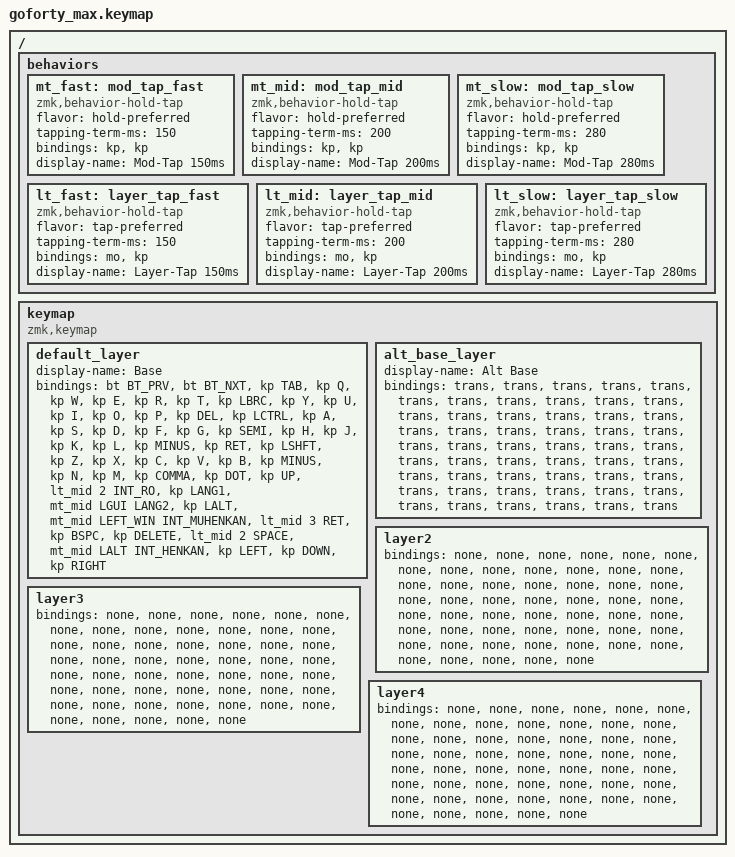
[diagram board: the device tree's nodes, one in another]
#include <behaviors.dtsi>
#include <behaviors/runtime_macro.dtsi>
#include <dt-bindings/zmk/bt.h>
#include <behaviors/runtime_tap_dance.dtsi>
#include <dt-bindings/zmk/keys.h>
#include <dt-bindings/zmk/pointing.h>

/ {
    behaviors {
        /* --- タップ/ホールドの判定時間プリセット ---
           押している時間がここで指定した ms を超えたら「ホールド」、
           それより短ければ「タップ」と判定される。
           数値ちがいのインスタンスを並べて定義しておくと、Keeb-On! Studio の
           キー割り当て候補にそのまま並び、キーごとに好みの速さを選べる。
           値そのものはコンパイル時固定だが、ファームウェアはタグを打てば
           GitHub Releases から配布されるので、合わなければ数値を変えて再配布する。

           flavor は ZMK 標準に合わせてある:
             mod-tap 系   = hold-preferred (ZMK の &mt と同じ)
             layer-tap 系 = tap-preferred  (ZMK の &lt と同じ)
           なので mt_mid / lt_mid は標準の &mt / &lt と完全に同じ挙動になる。 */

        mt_fast: mod_tap_fast {
            compatible = "zmk,behavior-hold-tap";
            #binding-cells = <2>;
            flavor = "hold-preferred";
            tapping-term-ms = <150>;
            bindings = <&kp>, <&kp>;
            display-name = "Mod-Tap 150ms";
        };

        mt_mid: mod_tap_mid {
            compatible = "zmk,behavior-hold-tap";
            #binding-cells = <2>;
            flavor = "hold-preferred";
            tapping-term-ms = <200>;
            bindings = <&kp>, <&kp>;
            display-name = "Mod-Tap 200ms";
        };

        mt_slow: mod_tap_slow {
            compatible = "zmk,behavior-hold-tap";
            #binding-cells = <2>;
            flavor = "hold-preferred";
            tapping-term-ms = <280>;
            bindings = <&kp>, <&kp>;
            display-name = "Mod-Tap 280ms";
        };

        lt_fast: layer_tap_fast {
            compatible = "zmk,behavior-hold-tap";
            #binding-cells = <2>;
            flavor = "tap-preferred";
            tapping-term-ms = <150>;
            bindings = <&mo>, <&kp>;
            display-name = "Layer-Tap 150ms";
        };

        lt_mid: layer_tap_mid {
            compatible = "zmk,behavior-hold-tap";
            #binding-cells = <2>;
            flavor = "tap-preferred";
            tapping-term-ms = <200>;
            bindings = <&mo>, <&kp>;
            display-name = "Layer-Tap 200ms";
        };

        lt_slow: layer_tap_slow {
            compatible = "zmk,behavior-hold-tap";
            #binding-cells = <2>;
            flavor = "tap-preferred";
            tapping-term-ms = <280>;
            bindings = <&mo>, <&kp>;
            display-name = "Layer-Tap 280ms";
        };
    };

    keymap {
        compatible = "zmk,keymap";

        default_layer {
            display-name = "Base";
            // Layer 0: o51go の Remap キーマップと同一構成(BTキー2個の追加のみ)

            bindings = <
&bt BT_PRV  &bt BT_NXT  &kp TAB  &kp Q  &kp W  &kp E  &kp R  &kp T  &kp LBRC  &kp Y  &kp U  &kp I  &kp O  &kp P  &kp DEL  &kp LCTRL  &kp A  &kp S  &kp D  &kp F  &kp G  &kp SEMI  &kp H  &kp J  &kp K  &kp L  &kp MINUS  &kp RET  &kp LSHFT  &kp Z  &kp X  &kp C  &kp V  &kp B  &kp MINUS  &kp N  &kp M  &kp COMMA  &kp DOT  &kp UP  &lt_mid 2 INT_RO  &kp LANG1  &mt_mid LGUI LANG2  &kp LALT  &mt_mid LEFT_WIN INT_MUHENKAN  &lt_mid 3 RET  &kp BSPC  &kp DELETE  &lt_mid 2 SPACE  &mt_mid LALT INT_HENKAN  &kp LEFT  &kp DOWN  &kp RIGHT
            >;
        };

        alt_base_layer {
            display-name = "Alt Base";
            // Layer 1: もう一方のOS用のベース。OS検出がデフォルトレイヤーを
            // 0 と 1 で切り替える (CONFIG_ZMK_DEFAULT_LAYER_OS_DETECTION)。
            //
            // ここが「デフォルトレイヤー」になったときは、これより下の
            // レイヤーは参照されない: zmk_keymap_position_state_changed() の
            // 走査はデフォルトレイヤーで止まる。つまり &trans のままだと
            // 切り替えた瞬間に全キーが無反応になる。
            // Keeb-On! Studio の「Baseからコピー」で埋めてから使うこと。
            //
            // 位置は 1 でなければならない。&lt_mid で押さえるレイヤーは
            // デフォルトより上(番号が大きい)である必要があるため、
            // ここに割り込ませて既存のレイヤーを1つずつ繰り下げてある。

            bindings = <
&trans  &trans  &trans  &trans  &trans  &trans  &trans  &trans  &trans  &trans  &trans  &trans  &trans  &trans  &trans  &trans  &trans  &trans  &trans  &trans  &trans  &trans  &trans  &trans  &trans  &trans  &trans  &trans  &trans  &trans  &trans  &trans  &trans  &trans  &trans  &trans  &trans  &trans  &trans  &trans  &trans  &trans  &trans  &trans  &trans  &trans  &trans  &trans  &trans  &trans  &trans  &trans  &trans
            >;
        };

        layer2 {
            // Layer 2: 空。ビルド後に Keeb-On! Studio から自由に割り当てる。
            //
            // 先頭キーは一時期 &studio_unlock だった。Studio のロックをやめた
            // ので不要になり、外してある。経緯は .conf に書いた。

            bindings = <
&none  &none  &none  &none  &none  &none  &none  &none  &none  &none  &none  &none  &none  &none  &none  &none  &none  &none  &none  &none  &none  &none  &none  &none  &none  &none  &none  &none  &none  &none  &none  &none  &none  &none  &none  &none  &none  &none  &none  &none  &none  &none  &none  &none  &none  &none  &none  &none  &none  &none  &none  &none  &none
            >;
        };

        layer3 {
            // Layer 3: 空。ZMK Studioから割り当てる。

            bindings = <
&none  &none  &none  &none  &none  &none  &none  &none  &none  &none  &none  &none  &none  &none  &none  &none  &none  &none  &none  &none  &none  &none  &none  &none  &none  &none  &none  &none  &none  &none  &none  &none  &none  &none  &none  &none  &none  &none  &none  &none  &none  &none  &none  &none  &none  &none  &none  &none  &none  &none  &none  &none  &none
            >;
        };

        layer4 {
            // Layer 4: 空。ZMK Studioから割り当てる。

            bindings = <
&none  &none  &none  &none  &none  &none  &none  &none  &none  &none  &none  &none  &none  &none  &none  &none  &none  &none  &none  &none  &none  &none  &none  &none  &none  &none  &none  &none  &none  &none  &none  &none  &none  &none  &none  &none  &none  &none  &none  &none  &none  &none  &none  &none  &none  &none  &none  &none  &none  &none  &none  &none  &none
            >;
        };
    };
};
